# ATSAM4SD32B register map
Vendor: Atmel; Series: SAM4S; File version: 0
CPU: CM4 r0p1, selectable endian, MPU, no FPU, 4 interrupt priority bits
Registers are 32-bit, read-write, reset 0x0 unless marked. A register's access mark holds for its fields unless they carry their own. Offsets are from the block's base; [hi:lo] are bit positions; {n}, {i} and the like mark numbered series.

## CRCCU — Cyclic Redundancy Check Calculation Unit
Base 0x40044000; register names take the prefix CRCCU_
0x00 DSCR — CRCCU Descriptor Base Register
  [31:9] DSCR — Descriptor Base Address
0x08 DMA_EN wo — CRCCU DMA Enable Register
  [0] DMAEN — DMA Enable Register
0x0C DMA_DIS wo — CRCCU DMA Disable Register
  [0] DMADIS — DMA Disable Register
0x10 DMA_SR ro — CRCCU DMA Status Register
  [0] DMASR — DMA Status Register
0x14 DMA_IER wo — CRCCU DMA Interrupt Enable Register
  [0] DMAIER — Interrupt Enable register
0x18 DMA_IDR wo — CRCCU DMA Interrupt Disable Register
  [0] DMAIDR — Interrupt Disable register
0x1C DMA_IMR ro — CRCCU DMA Interrupt Mask Register
  [0] DMAIMR — Interrupt Mask Register
0x20 DMA_ISR ro — CRCCU DMA Interrupt Status Register
  [0] DMAISR — Interrupt Status register
0x34 CR wo — CRCCU Control Register
  [0] RESET — CRC Computation Reset
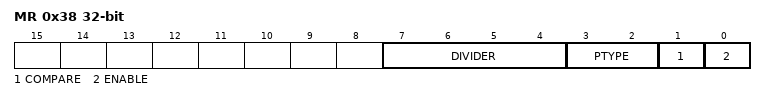
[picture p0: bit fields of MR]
0x38 MR — CRCCU Mode Register
  [7:4] DIVIDER — Request Divider
  [3:2] PTYPE — Primitive Polynomial
    0=CCITT8023 (Polynom 0x04C11DB7); 1=CASTAGNOLI (Polynom 0x1EDC6F41); 2=CCITT16 (Polynom 0x1021)
  [1] COMPARE — CRC Compare
  [0] ENABLE — CRC Enable
0x3C SR ro reset 0xFFFFFFFF — CRCCU Status Register
  [31:0] CRC — Cyclic Redundancy Check Value
0x40 IER wo — CRCCU Interrupt Enable Register
  [0] ERRIER — CRC Error Interrupt Enable
0x44 IDR wo — CRCCU Interrupt Disable Register
  [0] ERRIDR — CRC Error Interrupt Disable
0x48 IMR ro — CRCCU Interrupt Mask Register
  [0] ERRIMR — CRC Error Interrupt Mask
0x4C ISR ro — CRCCU Interrupt Status Register
  [0] ERRISR — CRC Error Interrupt Status

## CMCC — Cortex M Cache Controller
Base 0x4007C000; register names take the prefix CMCC_
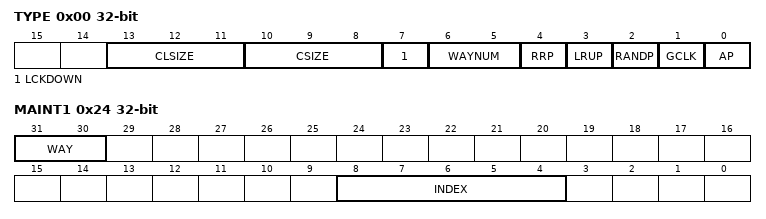
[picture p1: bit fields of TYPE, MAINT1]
0x00 TYPE ro reset not defined — Cache Type Register
  [13:11] CLSIZE — Cache Size
    0=CLSIZE_1KB (4 Bytes); 1=CLSIZE_2KB (8 Bytes); 2=CLSIZE_4KB (16 Bytes); 3=CLSIZE_8KB (32 Bytes)
  [10:8] CSIZE — Cache Size
    0=CSIZE_1KB (Cache Size 1 Kbytes); 1=CSIZE_2KB (Cache Size 2 Kbytes); 2=CSIZE_4KB (Cache Size 4 Kbytes); 3=CSIZE_8KB (Cache Size 8 Kbytes)
  [7] LCKDOWN — Lock Down Supported
  [6:5] WAYNUM — Number of Way
    0=DMAPPED (Direct Mapped Cache); 1=ARCH2WAY (2-WAY set associative); 2=ARCH4WAY (4-WAY set associative); 3=ARCH8WAY (8-WAY set associative)
  [4] RRP — Random Selection Policy Supported
  [3] LRUP — Least Recently Used Policy Supported
  [2] RANDP — Random Selection Policy Supported
  [1] GCLK — Dynamic Clock Gating Supported
  [0] AP — Access Port Access Allowed
0x04 CFG — Cache Configuration Register
  [0] GCLKDIS — Disable Clock Gating
0x08 CTRL wo — Cache Control Register
  [0] CEN — Cache Controller Enable
0x0C SR ro reset 0x1 — Cache Status Register
  [0] CSTS — Cache Controller Status
0x20 MAINT0 wo reset not defined — Cache Maintenance Register 0
  [0] INVALL — Cache Controller Invalidate All
0x24 MAINT1 wo reset not defined — Cache Maintenance Register 1
  [31:30] WAY — Invalidate Way
    {v}=Way {v} is selection for index invalidation (v=0..3)
  [8:4] INDEX — Invalidate Index
0x28 MCFG — Cache Monitor Configuration Register
  [1:0] MODE — Cache Controller Monitor Counter Mode
    0=CYCLE_COUNT (Cycle counter); 1=IHIT_COUNT (Instruction hit counter); 2=DHIT_COUNT (Data hit counter)
0x2C MEN — Cache Monitor Enable Register
  [0] MENABLE — Cache Controller Monitor Enable
0x30 MCTRL wo reset not defined — Cache Monitor Control Register
  [0] SWRST — Monitor
0x34 MSR ro — Cache Monitor Status Register
  [31:0] EVENT_CNT — Monitor Event Counter

## MATRIX — AHB Bus Matrix
Base 0x400E0200
{0x0+4i} MATRIX_MCFG[{i}] (i=0..3) reset not defined — Master Configuration Register
  [2:0] ULBT — Undefined Length Burst Type
    0=INFINITE (No predicted end of burst is generated and therefore INCR bursts coming from this master cannot be broken.); 1=SINGLE (The undefined length burst is treated as a succession of single access allowing rearbitration at each beat of the INCR burst.); 2=FOUR_BEAT (The undefined length burst is split into a 4-beat bursts allowing rearbitration at each 4-beat burst end.); 3=EIGHT_BEAT (The undefined length burst is split into 8-beat bursts allowing rearbitration at each 8-beat burst end.); 4=SIXTEEN_BEAT (The undefined length burst is split into 16-beat bursts allowing rearbitration at each 16-beat burst end.)
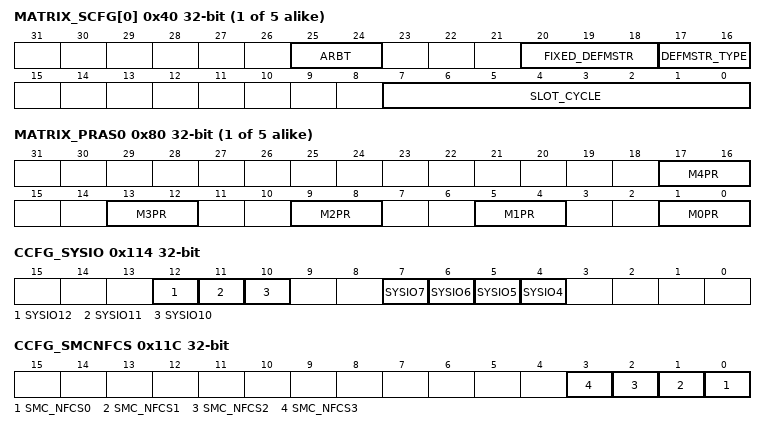
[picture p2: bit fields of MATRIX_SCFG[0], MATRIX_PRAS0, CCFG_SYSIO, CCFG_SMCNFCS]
{0x40+4i} MATRIX_SCFG[{i}] (i=0..4) reset not defined — Slave Configuration Register
  [25:24] ARBT — Arbitration Type
    0=ROUND_ROBIN (Round-robin arbitration); 1=FIXED_PRIORITY (Fixed priority arbitration)
  [20:18] FIXED_DEFMSTR — Fixed Default Master
  [17:16] DEFMSTR_TYPE — Default Master Type
    0=NO_DEFAULT (At the end of current slave access, if no other master request is pending, the slave is disconnected from all masters.This results in having a one cycle latency for the first access of a burst transfer or for a single access.); 1=LAST (At the end of current slave access, if no other master request is pending, the slave stays connected to the last master having accessed it.This results in not having the one cycle latency when the last master tries to access the slave again.); 2=FIXED (At the end of the current slave access, if no other master request is pending, the slave connects to the fixed master the number that has been written in the FIXED_DEFMSTR field.This results in not having the one cycle latency when the fixed master tries to access the slave again.)
  [7:0] SLOT_CYCLE — Maximum Number of Allowed Cycles for a Burst
{0x80+8i} MATRIX_PRAS{i} (i=0..4) — Priority Register A for Slave {i}
  [4n+1:4n] M{n}PR (n=0..4) — Master {n} Priority
0x114 CCFG_SYSIO — System I/O Configuration register
  [12] SYSIO12 — PB12 or ERASE Assignment
  [11] SYSIO11 — PB11 or DDP Assignment
  [10] SYSIO10 — PB10 or DDM Assignment
  [7] SYSIO7 — PB7 or TCK/SWCLK Assignment
  [6] SYSIO6 — PB6 or TMS/SWDIO Assignment
  [5] SYSIO5 — PB5 or TDO/TRACESWO Assignment
  [4] SYSIO4 — PB4 or TDI Assignment
0x11C CCFG_SMCNFCS — SMC Chip Select NAND Flash Assignment Register
  [n] SMC_NFCS{n} (n=0..3) — SMC NAND Flash Chip Select {n} Assignment
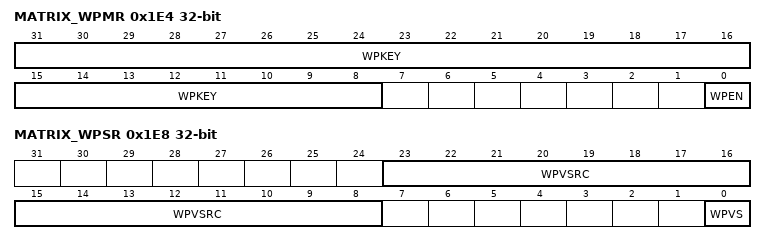
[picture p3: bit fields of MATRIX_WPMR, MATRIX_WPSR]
0x1E4 MATRIX_WPMR — Write Protection Mode Register
  [31:8] WPKEY — Write Protect Key
    0x4D4154=PASSWD (Writing any other value in this field aborts the write operation of the WPEN bit. Always reads as 0.)
  [0] WPEN — Write Protection Enable
0x1E8 MATRIX_WPSR ro — Write Protection Status Register
  [23:8] WPVSRC — Write Protection Violation Source
  [0] WPVS — Write Protection Violation Status

## Notices in the file
SAM Software Package License
Copyright (c) 2014, Atmel Corporation
All rights reserved.
Redistribution and use in source and binary forms, with or without
modification, are permitted provided that the following condition is met:
- Redistributions of source code must retain the above copyright notice,
this list of conditions and the disclaimer below.
Atmel's name may not be used to endorse or promote products derived from
this software without specific prior written permission.
DISCLAIMER:  THIS SOFTWARE IS PROVIDED BY ATMEL "AS IS" AND ANY EXPRESS OR
IMPLIED WARRANTIES, INCLUDING, BUT NOT LIMITED TO, THE IMPLIED WARRANTIES OF
MERCHANTABILITY, FITNESS FOR A PARTICULAR PURPOSE AND NON-INFRINGEMENT ARE
DISCLAIMED. IN NO EVENT SHALL ATMEL BE LIABLE FOR ANY DIRECT, INDIRECT,
INCIDENTAL, SPECIAL, EXEMPLARY, OR CONSEQUENTIAL DAMAGES (INCLUDING, BUT NOT
LIMITED TO, PROCUREMENT OF SUBSTITUTE GOODS OR SERVICES; LOSS OF USE, DATA,
OR PROFITS; OR BUSINESS INTERRUPTION) HOWEVER CAUSED AND ON ANY THEORY OF
LIABILITY, WHETHER IN CONTRACT, STRICT LIABILITY, OR TORT (INCLUDING
NEGLIGENCE OR OTHERWISE) ARISING IN ANY WAY OUT OF THE USE OF THIS SOFTWARE,
EVEN IF ADVISED OF THE POSSIBILITY OF SUCH DAMAGE.
